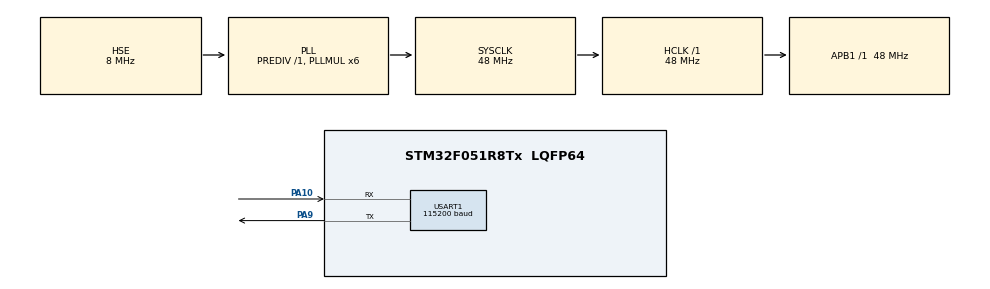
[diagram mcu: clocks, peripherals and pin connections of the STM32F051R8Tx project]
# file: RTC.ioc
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Mcu.Family=STM32F0
Mcu.Name=STM32F051R8Tx
Mcu.Package=LQFP64
PA10.Mode=Asynchronous
PA10.Signal=USART1_RX
PA13.Mode=Serial_Wire
PA13.Signal=SYS_SWDIO
PA14.Mode=Serial_Wire
PA14.Signal=SYS_SWCLK
PA9.Mode=Asynchronous
PA9.Signal=USART1_TX
PF0-OSC_IN.Mode=HSE-External-Oscillator
PF0-OSC_IN.Signal=RCC_OSC_IN
PF1-OSC_OUT.Mode=HSE-External-Oscillator
PF1-OSC_OUT.Signal=RCC_OSC_OUT
ProjectManager.HeapSize=0x200
ProjectManager.StackSize=0x400
ProjectManager.TargetToolchain=STM32CubeIDE
RCC.AHBFreq_Value=48000000
RCC.APB1Freq_Value=48000000
RCC.APB1TimFreq_Value=48000000
RCC.HCLKFreq_Value=48000000
RCC.PLLMUL=RCC_PLL_MUL6
RCC.PLLSourceVirtual=RCC_PLLSOURCE_HSE
RCC.SYSCLKFreq_VALUE=48000000
RCC.SYSCLKSource=RCC_SYSCLKSOURCE_PLLCLK
RTC.AsynchPrediv=127
RTC.Date=24
RTC.Format=RTC_FORMAT_BIN
RTC.Hours=11
RTC.Minutes=11
RTC.Month=RTC_MONTH_SEPTEMBER
RTC.Seconds=0
RTC.SynchPrediv=320
RTC.WeekDay=RTC_WEEKDAY_TUESDAY
RTC.Year=24
USART1.BaudRate=115200
USART1.VirtualMode-Asynchronous=VM_ASYNC
VP_RTC_VS_RTC_Activate.Mode=RTC_Enabled
VP_RTC_VS_RTC_Calendar.Mode=RTC_Calendar
board=custom

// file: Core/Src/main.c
/* USER CODE BEGIN Header */
/**
  ******************************************************************************
  * @file           : main.c
  * @brief          : Main program body
  ******************************************************************************
  * @attention
  *
  * Copyright (c) 2024 STMicroelectronics.
  * All rights reserved.
  *
  * This software is licensed under terms that can be found in the LICENSE file
  * in the root directory of this software component.
  * If no LICENSE file comes with this software, it is provided AS-IS.
  *
  ******************************************************************************
  */
/* USER CODE END Header */
#include "main.h"

RTC_HandleTypeDef hrtc;

UART_HandleTypeDef huart1;

void SystemClock_Config(void);
static void MX_GPIO_Init(void);
static void MX_USART1_UART_Init(void);
static void MX_RTC_Init(void);

/* USER CODE BEGIN 0 */

// uint8_t sDate;
uint8_t date[100];

/* USER CODE END 0 */

int main(void)
{

  /* MCU Configuration--------------------------------------------------------*/

  /* Reset of all peripherals, Initializes the Flash interface and the Systick. */
  HAL_Init();

  /* Configure the system clock */
  SystemClock_Config();

  /* Initialize all configured peripherals */
  MX_GPIO_Init();
  MX_USART1_UART_Init();
  MX_RTC_Init();

  /* Infinite loop */
  while (1)
  {

    /* USER CODE BEGIN 3 */
	RTC_DateTypeDef gDate;
	RTC_TimeTypeDef gTime;

	/* Get the RTC current Time */
	HAL_RTC_GetTime(&hrtc, &gTime, RTC_FORMAT_BIN);
	/* Get the RTC current Date */
	HAL_RTC_GetDate(&hrtc, &gDate, RTC_FORMAT_BIN);

	sprintf(date, "%02d-%02d-%02d %02d:%02d:%02d:%02d\r\n",
			gDate.Year + 2000, gDate.Month, gDate.Date, gTime.Hours, gTime.Minutes, gTime.Seconds, gTime.SubSeconds);
	HAL_UART_Transmit(&huart1, (uint8_t*)date, 30, 1000);
	HAL_Delay(500);
  }
  /* USER CODE END 3 */
}

void SystemClock_Config(void)
{
  RCC_OscInitTypeDef RCC_OscInitStruct = {0};
  RCC_ClkInitTypeDef RCC_ClkInitStruct = {0};
  RCC_PeriphCLKInitTypeDef PeriphClkInit = {0};

  /** Initializes the RCC Oscillators according to the specified parameters
  * in the RCC_OscInitTypeDef structure.
  */
  RCC_OscInitStruct.OscillatorType = RCC_OSCILLATORTYPE_LSI|RCC_OSCILLATORTYPE_HSE;
  RCC_OscInitStruct.HSEState = RCC_HSE_ON;
  RCC_OscInitStruct.LSIState = RCC_LSI_ON;
  RCC_OscInitStruct.PLL.PLLState = RCC_PLL_ON;
  RCC_OscInitStruct.PLL.PLLSource = RCC_PLLSOURCE_HSE;
  RCC_OscInitStruct.PLL.PLLMUL = RCC_PLL_MUL6;
  RCC_OscInitStruct.PLL.PREDIV = RCC_PREDIV_DIV1;
  if (HAL_RCC_OscConfig(&RCC_OscInitStruct) != HAL_OK)
  {
    Error_Handler();
  }

  /** Initializes the CPU, AHB and APB buses clocks
  */
  RCC_ClkInitStruct.ClockType = RCC_CLOCKTYPE_HCLK|RCC_CLOCKTYPE_SYSCLK
                              |RCC_CLOCKTYPE_PCLK1;
  RCC_ClkInitStruct.SYSCLKSource = RCC_SYSCLKSOURCE_PLLCLK;
  RCC_ClkInitStruct.AHBCLKDivider = RCC_SYSCLK_DIV1;
  RCC_ClkInitStruct.APB1CLKDivider = RCC_HCLK_DIV1;

  if (HAL_RCC_ClockConfig(&RCC_ClkInitStruct, FLASH_LATENCY_1) != HAL_OK)
  {
    Error_Handler();
  }
  PeriphClkInit.PeriphClockSelection = RCC_PERIPHCLK_USART1|RCC_PERIPHCLK_RTC;
  PeriphClkInit.Usart1ClockSelection = RCC_USART1CLKSOURCE_PCLK1;
  PeriphClkInit.RTCClockSelection = RCC_RTCCLKSOURCE_LSI;
  if (HAL_RCCEx_PeriphCLKConfig(&PeriphClkInit) != HAL_OK)
  {
    Error_Handler();
  }
}

static void MX_RTC_Init(void)
{

  RTC_TimeTypeDef sTime = {0};
  RTC_DateTypeDef sDate = {0};

  /** Initialize RTC Only
  */
  hrtc.Instance = RTC;
  hrtc.Init.HourFormat = RTC_HOURFORMAT_24;
  hrtc.Init.AsynchPrediv = 127;
  hrtc.Init.SynchPrediv = 320;
  hrtc.Init.OutPut = RTC_OUTPUT_DISABLE;
  hrtc.Init.OutPutPolarity = RTC_OUTPUT_POLARITY_HIGH;
  hrtc.Init.OutPutType = RTC_OUTPUT_TYPE_OPENDRAIN;
  if (HAL_RTC_Init(&hrtc) != HAL_OK)
  {
    Error_Handler();
  }

  /** Initialize RTC and set the Time and Date
  */
  sTime.Hours = 11;
  sTime.Minutes = 37;
  sTime.Seconds = 0;
  sTime.DayLightSaving = RTC_DAYLIGHTSAVING_NONE;
  sTime.StoreOperation = RTC_STOREOPERATION_RESET;
  if (HAL_RTC_SetTime(&hrtc, &sTime, RTC_FORMAT_BIN) != HAL_OK)
  {
    Error_Handler();
  }
  sDate.WeekDay = RTC_WEEKDAY_TUESDAY;
  sDate.Month = RTC_MONTH_SEPTEMBER;
  sDate.Date = 24;
  sDate.Year = 24;

  if (HAL_RTC_SetDate(&hrtc, &sDate, RTC_FORMAT_BIN) != HAL_OK)
  {
    Error_Handler();
  }

}

static void MX_USART1_UART_Init(void)
{

  huart1.Instance = USART1;
  huart1.Init.BaudRate = 115200;
  huart1.Init.WordLength = UART_WORDLENGTH_8B;
  huart1.Init.StopBits = UART_STOPBITS_1;
  huart1.Init.Parity = UART_PARITY_NONE;
  huart1.Init.Mode = UART_MODE_TX_RX;
  huart1.Init.HwFlowCtl = UART_HWCONTROL_NONE;
  huart1.Init.OverSampling = UART_OVERSAMPLING_16;
  huart1.Init.OneBitSampling = UART_ONE_BIT_SAMPLE_DISABLE;
  huart1.AdvancedInit.AdvFeatureInit = UART_ADVFEATURE_NO_INIT;
  if (HAL_UART_Init(&huart1) != HAL_OK)
  {
    Error_Handler();
  }

}

static void MX_GPIO_Init(void)
{

  /* GPIO Ports Clock Enable */
  __HAL_RCC_GPIOF_CLK_ENABLE();
  __HAL_RCC_GPIOA_CLK_ENABLE();

}

void Error_Handler(void)
{
  __disable_irq();
  while (1)
  {
  }
}
